# RS1xxxx register map
Vendor: Silicon Lab Inc.; Series: ARMCM4; File version: 1.2
CPU: CM4 r1p0, little endian, MPU, FPU, 6 interrupt priority bits
Registers are 32-bit, read-write, reset 0x0 unless marked. A register's access mark holds for its fields unless they carry their own. Offsets are from the block's base; [hi:lo] are bit positions; {n}, {i} and the like mark numbered series.

## M4CLK — MCU HP (High Performance) domain contains the Cortex-M4F Processor, FPU, Debugger, MCU High Speed Interfaces, MCU HP Peripherals, MCU HP DMA and MCU/SZP shareable Interfaces
Base 0x46000000
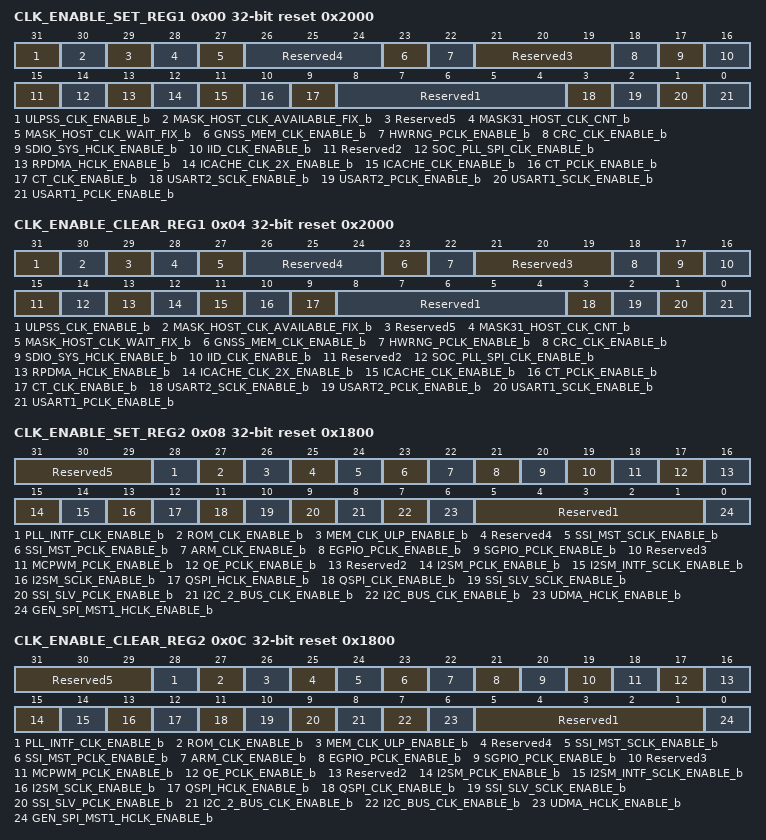
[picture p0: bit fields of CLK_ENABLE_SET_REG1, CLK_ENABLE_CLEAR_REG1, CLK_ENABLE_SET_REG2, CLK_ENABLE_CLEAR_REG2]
0x00 CLK_ENABLE_SET_REG1 reset 0x2000 — Clock Enable Set Register 1
  [31] ULPSS_CLK_ENABLE_b — Static Clock gating Enable for m4 soc_clk to ulpss1'b1 => Clock is enabled 1'b0 => Invalid.
  [30] MASK_HOST_CLK_AVAILABLE_FIX_b — This bit decides whether to consider negedge of host_clk_available in the generation of clock enable for host_clk gate in host mux 1'b1 => Don't consider 1'b0 => Invalid This bit along with mask_host_clk_wait_fix and mask31_host_clk_cnt are to take care in case of any bugs.
  [29] Reserved5 — It is recommended to write these bits to 0.
  [28] MASK31_HOST_CLK_CNT_b — When mask_host_clk_wait_fix is 1'b1, this bit decides whether to count for 32 0r 16 xtal clock cycles to come out of WAIT state in host mux FSM 1'b1 => Wait for 32 clock cycles 1'b0 => Invalid This bit along with mask_host_clk_available_fix and mask_host_clk_wait_fix are to take care in case of any bugs.
  [27] MASK_HOST_CLK_WAIT_FIX_b — This bit decides whether to wait for a fixed number of xtal clock cycles(based on mask31_host_clk_cnt) or wait for a internally generated signal to come out of WAIT state in host mux FSM 1'b1 => Wait for fixed number of xtal clk cycles 1'b0 => Invalid This bit along with mask_host_clk_available_fix and mask31_host_clk_cnt are to take care in case of any bugs.
  [26:24] Reserved4 — It is recommended to write these bits to 0.
  [23] GNSS_MEM_CLK_ENABLE_b — Static Clock gating Enable for GNSS mem clk1'b1 => Clock is enabled 1'b0 => Invalid
  [22] HWRNG_PCLK_ENABLE_b — Static Clock gating Enable for HWRNG pclk1'b1 => Clock is enabled 1'b0 => Invalid.
  [21:19] Reserved3 — It is recommended to write these bits to 0.
  [18] CRC_CLK_ENABLE_b — Static Clock gating Enable for crc clk1'b1 => Clock is enabled 1'b0 => Invalid
  [17] SDIO_SYS_HCLK_ENABLE_b — Static Clock gating Enable for sdio sys hclk1'b1 => Clock is enabled 1'b0 => Invalid
  [16] IID_CLK_ENABLE_b — Static Clock gating Enable for iid clk1'b1 => Clock is enabled 1'b0 => Invalid.
  [15] Reserved2 — It is recommended to write these bits to 0.
  [14] SOC_PLL_SPI_CLK_ENABLE_b — Static Clock gating Enable for soc pll spi clk1'b1 => Clock is enabled 1'b0 => Invalid.
  [13] RPDMA_HCLK_ENABLE_b — Static Clock gating Enable for rpdma hclk1'b1 => Clock is enabled 1'b0 => Invalid.
  [12] ICACHE_CLK_2X_ENABLE_b — Static Clock gating Enable for icache 2x clk1'b1 => Clock is enabled 1'b0 => Invalid.
  [11] ICACHE_CLK_ENABLE_b — Static Clock gating Enable for icache clk1'b1 => Clock is enabled 1'b0 => Invalid.
  [10] CT_PCLK_ENABLE_b — Static Clock gating Enable for sct pclk1'b1 => Clock is enabled 1'b0 => Invalid.
  [9] CT_CLK_ENABLE_b — Static Clock gating Enable for sct clk1'b1 => Clock is enabled 1'b0 => Invalid.
  [8:4] Reserved1 — It is recommended to write these bits to 0.
  [3] USART2_SCLK_ENABLE_b — Static Clock gating Enable for usart2 sclk1'b1 => Clock is enabled 1'b0 => Invalid
  [2] USART2_PCLK_ENABLE_b — Static Clock gating Enable for usart2 pclk1'b1 => Clock is enabled 1'b0 => Invalid
  [1] USART1_SCLK_ENABLE_b — Static Clock gating Enable for usart1 sclk1'b1 => Clock is enabled 1'b0 => Invalid
  [0] USART1_PCLK_ENABLE_b — Static Clock gating Enable for usart1 pclk1'b1 => Clock is enabled 1'b0 => Invalid
0x04 CLK_ENABLE_CLEAR_REG1 reset 0x2000 — Clock Enable Clear Register 1
  [31] ULPSS_CLK_ENABLE_b — Static Clock gating Enable for m4 soc_clk to ulpss1'b1 => Clock is enabled 1'b0 => Invalid.
  [30] MASK_HOST_CLK_AVAILABLE_FIX_b — This bit decides whether to consider negedge of host_clk_available in the generation of clock enable for host_clk gate in host mux 1'b1 => Don't consider 1'b0 => Invalid This bit along with mask_host_clk_wait_fix and mask31_host_clk_cnt are to take care in case of any bugs.
  [29] Reserved5 — It is recommended to write these bits to 0.
  [28] MASK31_HOST_CLK_CNT_b — When mask_host_clk_wait_fix is 1'b1, this bit decides whether to count for 32 0r 16 xtal clock cycles to come out of WAIT state in host mux FSM 1'b1 => Wait for 32 clock cycles 1'b0 => Invalid This bit along with mask_host_clk_available_fix and mask_host_clk_wait_fix are to take care in case of any bugs.
  [27] MASK_HOST_CLK_WAIT_FIX_b — This bit decides whether to wait for a fixed number of xtal clock cycles(based on mask31_host_clk_cnt) or wait for a internally generated signal to come out of WAIT state in host mux FSM 1'b1 => Wait for fixed number of xtal clk cycles 1'b0 => Invalid This bit along with mask_host_clk_available_fix and mask31_host_clk_cnt are to take care in case of any bugs.
  [26:24] Reserved4 — It is recommended to write these bits to 0.
  [23] GNSS_MEM_CLK_ENABLE_b — Static Clock Clear for GNSS mem clk1'b1 => Clock is Clear 1'b0 => Invalid
  [22] HWRNG_PCLK_ENABLE_b — Static Clock Clear for HWRNG pclk1'b1 => Clock is Clear 1'b0 => Invalid.
  [21:19] Reserved3 — It is recommended to write these bits to 0.
  [18] CRC_CLK_ENABLE_b — Static Clock Clear for crc clk1'b1 => Clock is Clear 1'b0 => Invalid
  [17] SDIO_SYS_HCLK_ENABLE_b — Static Clock Clear for sdio sys hclk1'b1 => Clock is Clear 1'b0 => Invalid
  [16] IID_CLK_ENABLE_b — Static Clock Clear for iid clk1'b1 => Clock is Clear 1'b0 => Invalid.
  [15] Reserved2 — It is recommended to write these bits to 0.
  [14] SOC_PLL_SPI_CLK_ENABLE_b — Static Clock Clear for soc pll spi clk1'b1 => Clock is Clear 1'b0 => Invalid.
  [13] RPDMA_HCLK_ENABLE_b — Static Clock Clear for rpdma hclk1'b1 => Clock is Clear 1'b0 => Invalid.
  [12] ICACHE_CLK_2X_ENABLE_b — Static Clock Clear for icache 2x clk1'b1 => Clock is Clear 1'b0 => Invalid.
  [11] ICACHE_CLK_ENABLE_b — Static Clock Clear for icache clk1'b1 => Clock is Clear 1'b0 => Invalid.
  [10] CT_PCLK_ENABLE_b — Static Clock Clear for sct pclk1'b1 => Clock is Clear 1'b0 => Invalid.
  [9] CT_CLK_ENABLE_b — Static Clock Clear for sct clk1'b1 => Clock is Clear 1'b0 => Invalid.
  [8:4] Reserved1 — It is recommended to write these bits to 0.
  [3] USART2_SCLK_ENABLE_b — Static Clock Clear for usart2 sclk1'b1 => Clock is Clear 1'b0 => Invalid
  [2] USART2_PCLK_ENABLE_b — Static Clock Clear for usart2 pclk 1'b1 => Clock is Clear 1'b0 => Invalid
  [1] USART1_SCLK_ENABLE_b — Static Clock Clear for usart1 sclk1'b1 => Clock is Clear 1'b0 => Invalid
  [0] USART1_PCLK_ENABLE_b — Static Clock Clear for usart1 pclk1'b1 => Clock is Clear 1'b0 => Invalid
0x08 CLK_ENABLE_SET_REG2 reset 0x1800 — Clock Enable Set Register 2
  [31:29] Reserved5 — It is recommended to write these bits to 0.
  [28] PLL_INTF_CLK_ENABLE_b — Static Clock gating Enable for pll intf clk 1'b1 => Clock is enabled 1'b0 => Invalid.
  [27] ROM_CLK_ENABLE_b — Static Clock gating Enable for rom clk 1'b1 => Clock is enabled 1'b0 => Invalid.
  [26] MEM_CLK_ULP_ENABLE_b — Static Clock gating Enable for mem ulp clk 1'b1 => Clock is enabled 1'b0 => Invalid.
  [25] Reserved4 — It is recommended to write these bits to 0.
  [24] SSI_MST_SCLK_ENABLE_b — Static Clock gating Enable for ssi master sclk 1'b1 => Clock is enabled 1'b0 => Invalid.
  [23] SSI_MST_PCLK_ENABLE_b — Static Clock gating Enable for ssi master pclk 1'b1 => Clock is enabled 1'b0 => Invalid.
  [22] ARM_CLK_ENABLE_b — Static Clock gating Enable for arm clk 1'b1 => Clock is enabled 1'b0 => Invalid.
  [21] EGPIO_PCLK_ENABLE_b — Static Clock gating Enable for egpio pclk 1'b1 => Clock is enabled 1'b0 => Invalid.
  [20] SGPIO_PCLK_ENABLE_b — Static Clock gating Enable for sgpio pclk 1'b1 => Clock is enabled 1'b0 => Invalid.
  [19] Reserved3 — It is recommended to write these bits to 0.
  [18] MCPWM_PCLK_ENABLE_b — Static Clock gating Enable for mcpwm pclk 1'b1 => Clock is enabled 1'b0 => Invalid.
  [17] QE_PCLK_ENABLE_b — Static Clock gating Enable for qe pclk 1'b1 => Clock is enabled 1'b0 => Invalid.
  [16] Reserved2 — It is recommended to write these bits to 0.
  [15] I2SM_PCLK_ENABLE_b — Static Clock gating Enable for i2s master pclk 1'b1 => Clock is enabled 1'b0 => Invalid.
  [14] I2SM_INTF_SCLK_ENABLE_b — Static Clock gating Enable for i2s interface sclk 1'b1 => Clock is enabled 1'b0 => Invalid.
  [13] I2SM_SCLK_ENABLE_b — Static Clock gating Enable for sclk of I2S at Root Clock generation 1'b1 => Clock is enabled 1'b0 => Invalid.
  [12] QSPI_HCLK_ENABLE_b — Static Clock gating Enable for qspi hclk 1'b1 => Clock is enabled 1'b0 => Invalid.
  [11] QSPI_CLK_ENABLE_b — Static Clock gating Enable for qspi clk 1'b1 => Clock is enabled 1'b0 => Invalid.
  [10] SSI_SLV_SCLK_ENABLE_b — Static Clock gating Enable for ssi slave sclk 1'b1 => Clock is enabled 1'b0 => Invalid.
  [9] SSI_SLV_PCLK_ENABLE_b — Static Clock gating Enable for ssi slave pclk 1'b1 => Clock is enabled 1'b0 => Invalid.
  [8] I2C_2_BUS_CLK_ENABLE_b — Static Clock gating Enable for i2c-2 bus clk 1'b1 => Clock is enabled 1'b0 => Invalid.
  [7] I2C_BUS_CLK_ENABLE_b — Static Clock gating Enable for i2c-1 bus clk1'b1 => Clock is enabled 1'b0 => Invalid.
  [6] UDMA_HCLK_ENABLE_b — Static Clock gating Enable for udma hclk 1'b1 => Clock is enabled 1'b0 => Invalid.
  [5:1] Reserved1 — It is recommended to write these bits to 0.
  [0] GEN_SPI_MST1_HCLK_ENABLE_b — Static Clock gating Enable for gen spi master1 hclk 1'b1 => Clock is enabled 1'b0 => Invalid
0x0C CLK_ENABLE_CLEAR_REG2 reset 0x1800 — Clock Enable Clear Register 2
  [31:29] Reserved5 — It is recommended to write these bits to 0.
  [28] PLL_INTF_CLK_ENABLE_b — Static Clock Clear for pll intf clk 1'b1 => Clock is Clear 1'b0 => Invalid.
  [27] ROM_CLK_ENABLE_b — Static Clock Clear for rom clk 1'b1 => Clock is Clear 1'b0 => Invalid.
  [26] MEM_CLK_ULP_ENABLE_b — Static Clock Clear for mem ulp clk 1'b1 => Clock is Clear 1'b0 => Invalid.
  [25] Reserved4 — It is recommended to write these bits to 0.
  [24] SSI_MST_SCLK_ENABLE_b — Static Clock Clear for ssi master sclk 1'b1 => Clock is Clear 1'b0 => Invalid.
  [23] SSI_MST_PCLK_ENABLE_b — Static Clock Clear for ssi master pclk 1'b1 => Clock is Clear 1'b0 => Invalid.
  [22] ARM_CLK_ENABLE_b — Static Clock Clear for arm clk 1'b1 => Clock is Clear 1'b0 => Invalid.
  [21] EGPIO_PCLK_ENABLE_b — Static Clock Clear for egpio pclk 1'b1 => Clock is Clear 1'b0 => Invalid.
  [20] SGPIO_PCLK_ENABLE_b — Static Clock Clear for sgpio pclk 1'b1 => Clock is Clear 1'b0 => Invalid.
  [19] Reserved3 — It is recommended to write these bits to 0.
  [18] MCPWM_PCLK_ENABLE_b — Static Clock Clear for mcpwm pclk 1'b1 => Clock is Clear 1'b0 => Invalid.
  [17] QE_PCLK_ENABLE_b — Static Clock Clear for qe pclk 1'b1 => Clock is Clear 1'b0 => Invalid.
  [16] Reserved2 — It is recommended to write these bits to 0.
  [15] I2SM_PCLK_ENABLE_b — Static Clock Clear for i2s master pclk 1'b1 => Clock is Clear 1'b0 => Invalid.
  [14] I2SM_INTF_SCLK_ENABLE_b — Static Clock Clear for i2s interface sclk 1'b1 => Clock is Clear 1'b0 => Invalid.
  [13] I2SM_SCLK_ENABLE_b — Static Clock Clear for sclk of I2S at Root Clock generation 1'b1 => Clock is Clear 1'b0 => Invalid.
  [12] QSPI_HCLK_ENABLE_b — Static Clock Clear for qspi hclk 1'b1 => Clock is Clear 1'b0 => Invalid.
  [11] QSPI_CLK_ENABLE_b — Static Clock Clear for qspi clk 1'b1 => Clock is Clear 1'b0 => Invalid.
  [10] SSI_SLV_SCLK_ENABLE_b — Static Clock Clear for ssi slave sclk 1'b1 => Clock is Clear 1'b0 => Invalid.
  [9] SSI_SLV_PCLK_ENABLE_b — Static Clock Clear for ssi slave pclk 1'b1 => Clock is Clear 1'b0 => Invalid.
  [8] I2C_2_BUS_CLK_ENABLE_b — Static Clock Clear for i2c-2 bus clk 1'b1 => Clock is Clear 1'b0 => Invalid.
  [7] I2C_BUS_CLK_ENABLE_b — Static Clock Clear for i2c-1 bus clk1'b1 => Clock is Clear 1'b0 => Invalid.
  [6] UDMA_HCLK_ENABLE_b — Static Clock Clear for udma hclk 1'b1 => Clock is Clear 1'b0 => Invalid.
  [5:1] Reserved1 — It is recommended to write these bits to 0.
  [0] GEN_SPI_MST1_HCLK_ENABLE_b — Static Clock Clear for gen spi master1 hclk 1'b1 => Clock is Clear 1'b0 => Invalid
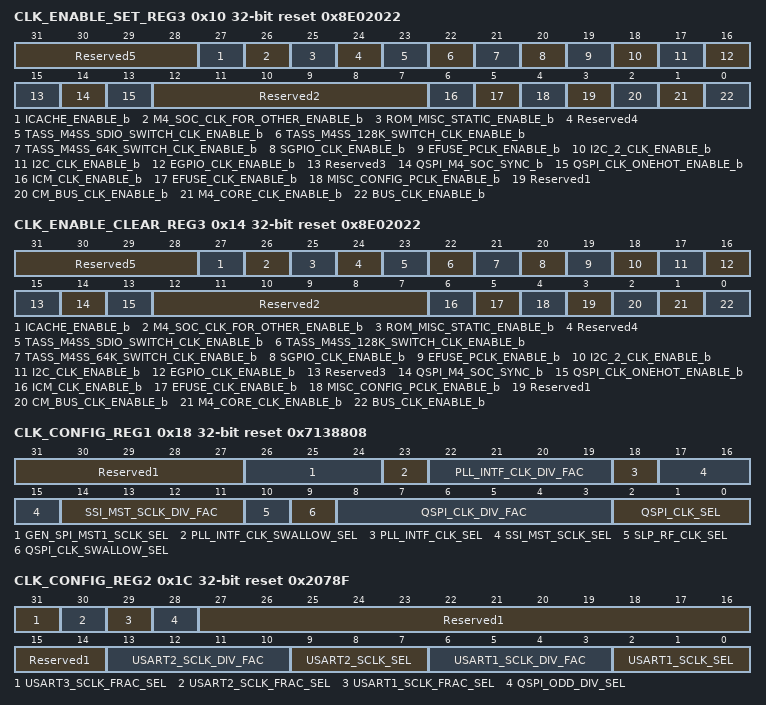
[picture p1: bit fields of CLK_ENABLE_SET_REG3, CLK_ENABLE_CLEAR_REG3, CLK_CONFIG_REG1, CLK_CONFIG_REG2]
0x10 CLK_ENABLE_SET_REG3 reset 0x8E02022 — Clock Enable Set Register 3
  [31:28] Reserved5 — It is recommended to write these bits to 0.
  [27] ICACHE_ENABLE_b — Static Clock gating enable for Icache. This has to be enable for Icache operations. 1b1 - Clock is enabled 1b0 - Invalid.
  [26] M4_SOC_CLK_FOR_OTHER_ENABLE_b — Static Clock gating enable for M4-SOC Other Clock 1b1 - Clock is enabled 1b0 - Invalid.
  [25] ROM_MISC_STATIC_ENABLE_b — Static Clock gating enable for rom ahb Clock 1b1 - Clock is enabled 1b0 - Invalid.
  [24] Reserved4 — It is recommended to write these bits to 0.
  [23] TASS_M4SS_SDIO_SWITCH_CLK_ENABLE_b — Unused.
  [22] TASS_M4SS_128K_SWITCH_CLK_ENABLE_b — Unused.
  [21] TASS_M4SS_64K_SWITCH_CLK_ENABLE_b — Unused.
  [20] SGPIO_CLK_ENABLE_b — Static Clock gating enable for SIO Module 1b1 - Clock is enabled 1b0 - Invalid.
  [19] EFUSE_PCLK_ENABLE_b — Static Clock gating enable for EFUSE APB Interface 1b1 - Clock is enabled 1b0 - Invalid.
  [18] I2C_2_CLK_ENABLE_b — Static Clock gating enable for I2C-2 Module 1b1 - Clock is enabled 1b0 - Invalid.
  [17] I2C_CLK_ENABLE_b — Static Clock gating enable for I2C-1 Module 1b1 - Clock is enabled 1b0 - Invalid.
  [16] EGPIO_CLK_ENABLE_b — Static Clock gating enable for Enhanced-GPIO 1b1 - Clock is enabled 1b0 - Invalid.
  [15] Reserved3 — It is recommended to write these bits to 0.
  [14] QSPI_M4_SOC_SYNC_b — Specifies whether QSPI clock is in sync with Soc clock. Before enabling this make sure that qspi_clk_onehot_enable is 1b0 to enable glitch free switching 1b1 - QSPI clock is in sync with M4 clock 1b0 - Invalid.
  [13] QSPI_CLK_ONEHOT_ENABLE_b — Static Clock gating Enable for QSPI clock generated from the dynamic mux 1b1 - Clock is enabled 1b0 - Invalid.
  [12:7] Reserved2 — It is recommended to write these bits to 0.
  [6] ICM_CLK_ENABLE_b — Static Clock gating Enable for icm clk 1'b1 => Clock is enabled 1'b0 => Invalid.
  [5] EFUSE_CLK_ENABLE_b — Static Clock gating Enable for efuse clk 1'b1 => Clock is enabled 1'b0 => Invalid.
  [4] MISC_CONFIG_PCLK_ENABLE_b — Static Clock gating Enable for misc config regs clk 1'b1 => Clock is enabled 1'b0 => Invalid.
  [3] Reserved1 — It is recommended to write these bits to 0.
  [2] CM_BUS_CLK_ENABLE_b — Static Clock gating Enable for cm bus clk1'b1 => Clock is enabled1'b0 => Invalid.
  [1] M4_CORE_CLK_ENABLE_b — Static Clock gating Enable for M4 Core clk 1'b1 => Clock is enabled 1'b0 => Invalid.
  [0] BUS_CLK_ENABLE_b — Static Clock gating Enable for bus clk 1'b1 => Clock is enabled 1'b0 => Invalid
0x14 CLK_ENABLE_CLEAR_REG3 reset 0x8E02022 — Clock Enable Clear Register 3
  [31:28] Reserved5 — It is recommended to write these bits to 0.
  [27] ICACHE_ENABLE_b — Static Clock Disable for Icache. This has to be enable for Icache operations. 1b1 - Clock is Disable 1b0 - Invalid.
  [26] M4_SOC_CLK_FOR_OTHER_ENABLE_b — Static Clock Disable for M4-SOC Other Clock 1b1 - Clock is Disable 1b0 - Invalid.
  [25] ROM_MISC_STATIC_ENABLE_b — Static Clock Disable for rom ahb Clock 1b1 - Clock is Disable 1b0 - Invalid.
  [24] Reserved4 — It is recommended to write these bits to 0.
  [23] TASS_M4SS_SDIO_SWITCH_CLK_ENABLE_b — Unused.
  [22] TASS_M4SS_128K_SWITCH_CLK_ENABLE_b — Unused.
  [21] TASS_M4SS_64K_SWITCH_CLK_ENABLE_b — Unused.
  [20] SGPIO_CLK_ENABLE_b — Static Clock gating enable for SIO Module 1b1 - Clock is enabled 1b0 - Invalid.
  [19] EFUSE_PCLK_ENABLE_b — Static Clock Disable for EFUSE APB Interface 1b1 - Clock is Disable 1b0 - Invalid.
  [18] I2C_2_CLK_ENABLE_b — Static Clock Disable for I2C-2 Module 1b1 - Clock is Disable 1b0 - Invalid.
  [17] I2C_CLK_ENABLE_b — Static Clock Disable for I2C-1 Module 1b1 - Clock is Disable 1b0 - Invalid.
  [16] EGPIO_CLK_ENABLE_b — Static Clock Disable for Enhanced-GPIO 1b1 - Clock is Disable 1b0 - Invalid.
  [15] Reserved3 — It is recommended to write these bits to 0.
  [14] QSPI_M4_SOC_SYNC_b — Specifies whether QSPI clock is in sync with Soc clock. Before enabling this make sure that qspi_clk_onehot_enable is 1b0 to enable glitch free switching 1b1 - QSPI clock is in sync with M4 clock 1b0 - Invalid.
  [13] QSPI_CLK_ONEHOT_ENABLE_b — Static Clock Clear for QSPI clock generated from the dynamic mux 1b1 - Clock is Gated 1b0 - Invalid.
  [12:7] Reserved2 — It is recommended to write these bits to 0.
  [6] ICM_CLK_ENABLE_b — Static Clock Clear for icm clk 1'b1 => Clock is Clear 1'b0 => Invalid.
  [5] EFUSE_CLK_ENABLE_b — Static Clock Clear for efuse clk 1'b1 => Clock is Clear 1'b0 => Invalid.
  [4] MISC_CONFIG_PCLK_ENABLE_b — Static Clock Clear for misc config regs clk 1'b1 => Clock is Clear 1'b0 => Invalid.
  [3] Reserved1 — It is recommended to write these bits to 0.
  [2] CM_BUS_CLK_ENABLE_b — Static Clock gating Enable for cm bus clk1'b1 => Clock is enabled1'b0 => Invalid.
  [1] M4_CORE_CLK_ENABLE_b — Static Clock Clear for M4 Core clk 1'b1 => Clock is Clear 1'b0 => Invalid.
  [0] BUS_CLK_ENABLE_b — Static Clock Clear for bus clk 1'b1 => Clock is Clear 1'b0 => Invalid
0x18 CLK_CONFIG_REG1 reset 0x7138808 — Clock Config Register 1
  [31:27] Reserved1 — It is recommended to write these bits to 0.
  [26:24] GEN_SPI_MST1_SCLK_SEL — Selects one of the following clocks for USART1 clk 000 - m4_soc_clk_for_other_clocks 001 - ulp ref Clock(generated inside M4SS based on m4ss_ref_clk_sel from NPSS) 010 - SoC PLL Clock(program bypass_soc_pll_clk if the bypass clock has to be selected) 011 - Modem PLL Clock2(Not Intended for the pragrammer) (program bypass_modem_pll_clk if the bypass clock has to be selected) 100 - Intf PLL Clock(program bypass_intf_pll_clk if the bypass clock has to be selected) 101 to 110 - Invalid 111 - Gated
  [23] PLL_INTF_CLK_SWALLOW_SEL — Clock select for clock swallow or clock divider for PLL INTF Clk 1b0 - 50% divider is selected with division factor 2; 1b1 - Swallowed clock is selected with division factor pll_intf_clk_div_fac
  [22:19] PLL_INTF_CLK_DIV_FAC — Clock division factor for pll_intf_clk. If pll_intf_clk_enable is 1b0 clock is gated. Else, when pll_intf_clk_swallow_sel is 1b1, output clock is a swallowed clock. when pll_intf_clk_swallow_sel is 1b0, output clock is a 50 Per duty cycle clock.
  [18] PLL_INTF_CLK_SEL — Selects one of the following clocks for pll intf clock 0 - Intf Pll Clock(program bypass_intf_pll_clk if the bypass clock has to be selected) 1 - SoC Pll Clock(program bypass_soc_pll_clk if the bypass clock has to be selected)
  [17:15] SSI_MST_SCLK_SEL — Selects one of the following clocks for ssi master 000 - ULP Ref Clock(generated inside M4SS based on m4ss_ref_clk_sel from NPSS) 001 - SoC PLL Clock(program bypass_soc_pll_clk if the bypass clock has to be selected) 010 - Modem PLL Clock1(Not Intended for the programmer) (program bypass_modem_pll_clk if the bypass clock has to be selected) 011 - Intf PLL Clock(program bypass_intf_pll_clk if the bypass clock has to be selected) 100 - Modem PLL Clock2(Not Intended for the pragrammer) (program bypass_modem_pll_clk if the bypass clock has to be selected) 101 - m4_soc_clk_for_other_clks 110 - Invalid 111 - Gated.
  [14:11] SSI_MST_SCLK_DIV_FAC — Clock division factor for ssi_mst_sclk. If ssi_mst_sclk_enable is 1b0 clock is gated. Else output clock is a swallowed clock with the following frequency. 4h0,4h1 => Divider is bypassed >4h1 => clk_out = clk_in/ ssi_mst_sclk_div_fac.
  [10] SLP_RF_CLK_SEL — clock select for m4_soc_rf_ref_clk 0 - m4_soc_clk 1 - rf_ref_clk.
  [9] QSPI_CLK_SWALLOW_SEL — Clock select for clock swallow or clock divider for QSPI 1b0 => 50% divider is selected with division factor qspi_clk_div_fac 1b1 => Swallowed clock is selected with division factor qspi_clk_div_fac Before Changing this ensure that the input clocks are gated
  [8:3] QSPI_CLK_DIV_FAC — Clock divison factor for QSPI. If qspi_clk_enable is 1b0 clock is gated. Else 1)when qspi_clk_swallow_sel is 1b1 and qspi_odd_div_sel is 1b0 output clock is a swallowed clock with the following frequency. 6h0,6h1 => clk_out = clk_in >6h1 => clk_out = clk_in/ qspi_clk_div_fac 2)when qspi_clk_swallow_sel is 1b0 and qspi_odd_div_sel is 1b0 output clock is a 50% duty cycle clock with the following frequency. 6h0 => clk_out = clk_in/2 >6h0 => clk_out = clk_in/ (2*qspi_clk_div_fac) 3)When qspi_odd_div_sel is 1b1, output clock is a 50% duty cycle clock with the following frequency. clk_out = clk_in/qspi_clk_div_fac when qspi_clk_div_fac is an odd number >=3, else output clock is gated
  [2:0] QSPI_CLK_SEL — Selects one of the following clocks for ssi master 000 - ULP Ref Clock(generated inside M4SS based on m4ss_ref_clk_sel from NPSS) 001 - Intf PLL Clock Clock (program bypass_intf_pll_clk if the bypass clock has to be selected) 010 - Modem PLL Clock2(Not Intended for the programmer) (program bypass_modem_pll_clk if the bypass clock has to be selected) 011 - SoC PLL Clock Clock (program bypass_soc_pll_clk if the bypass clock has to be selected) 100 to 110 - Invalid 111 - Gated
0x1C CLK_CONFIG_REG2 reset 0x2078F — Clock Config Register 1
  [31] USART3_SCLK_FRAC_SEL — Selects the type of divider for uart3_clk 1b0 - Clock Swallow is selected 1b1 - Fractional Divider is selected.
  [30] USART2_SCLK_FRAC_SEL — Selects the type of divider for uart2_clk 1b0 - Clock Swallow is selected 1b1 - Fractional Divider is selected.
  [29] USART1_SCLK_FRAC_SEL — Selects the type of divider for uart1_clk 1b0 - Clock Swallow is selected 1b1 - Fractional Divider is selected.
  [28] QSPI_ODD_DIV_SEL — Clock select for clock swallow or 50% even clock divider or 50% odd divider clock for QSPI 1b1 - 50% odd clock divider output is selected with division factor qspi_clk_div_fac 1b0 - 50% even clock divider output or swallowed is selected with division factor qspi_clk_div_fac based on qspi_clk_swallow_sel.
  [27:14] Reserved1 — It is recommended to write these bits to 0.
  [13:10] USART2_SCLK_DIV_FAC — Clock division factor for USART2 Clock. If usart2_sclk_enable is 1b0 clock is gated. Else output clock is a swallowed clock.
  [9:7] USART2_SCLK_SEL — Selects one of the following clocks for USART2 clk 000 - ulp ref Clock(generated inside M4SS based on m4ss_ref_clk_sel from NPSS) 001 - SoC PLL Clock(program bypass_soc_pll_clk if the bypass clock has to be selected) 010 - Modem PLL Clock2(Not Intended for the pragrammer)(program bypass_modem_pll_clk if the bypass clock has to be selected) 011 - Intf PLL Clock(program bypass_intf_pll_clk if the bypass clock has to be selected) 100 - m4_soc_clk_for_other_clocks 101 to 110 - Invalid 111 - Gated
  [6:3] USART1_SCLK_DIV_FAC — Clock division factor for USART1 Clock. If usart1_sclk_enable is 1b0 clock is gated. Else output clock is a swallowed clock.
  [2:0] USART1_SCLK_SEL — Selects one of the following clocks for USART1 clk 000 - ulp ref Clock(generated inside M4SS based on m4ss_ref_clk_sel from NPSS) 001 - SoC PLL Clock(program bypass_soc_pll_clk if the bypass clock has to be selected) 010 - Modem PLL Clock2(Not Intended for the pragrammer)(program bypass_modem_pll_clk if the bypass clock has to be selected) 011 - Intf PLL Clock(program bypass_intf_pll_clk if the bypass clock has to be selected) 100 - m4_soc_clk_for_other_clocks 101 to 110 - Invalid 111 - Gated
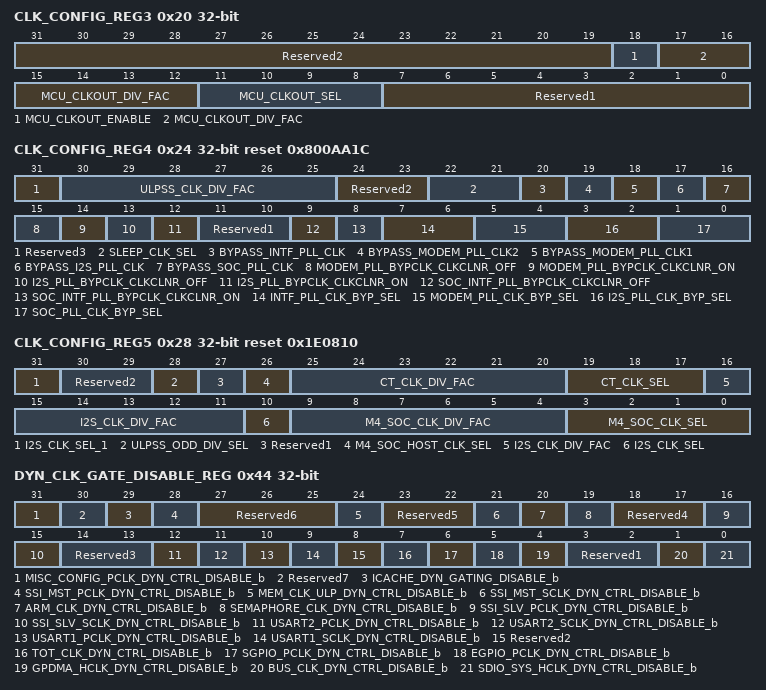
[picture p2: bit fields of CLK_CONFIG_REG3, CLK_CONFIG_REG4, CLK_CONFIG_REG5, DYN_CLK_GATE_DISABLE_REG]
0x20 CLK_CONFIG_REG3 — Clock Config Register 3
  [31:19] Reserved2 — It is recommended to write these bits to 0.
  [18] MCU_CLKOUT_ENABLE — Clock Enable for the clock on nwp_clkout (Mapped to GPIO) 1b0 - Clock is Gated 1b1 - Clock is Enabled
  [17:12] MCU_CLKOUT_DIV_FAC — Division factor for mcu_clkout (Mapped to GPIO)
  [11:8] MCU_CLKOUT_SEL — Clock Select for the clock on mcu_clkout (Mapped to GPIO)
  [7:0] Reserved1 — It is recommended to write these bits to 0.
0x24 CLK_CONFIG_REG4 reset 0x800AA1C — Clock Config Register 4
  [31] Reserved3 — It is recommended to write these bits to 0.
  [30:25] ULPSS_CLK_DIV_FAC — Clock division factor for clock to ULPSS. If ulpss_clk_enable is 1b0 clock is gated. Else output clock is a divided clock with the following frequency. 6h0 - Divider is bypassed > 6h0 - clk_out = clk_in/ 2* ulpss_clk_div_fac
  [24:23] Reserved2 — It is recommended to write these bits to 0.
  [22:21] SLEEP_CLK_SEL — Select to choose sleep clk 00 - ulp_32khz_rc_clk 01 - ulp_32khz_xtal_clk 10 - Gated 11 - ulp_32khz_ro_clk.
  [20] BYPASS_INTF_PLL_CLK — Select to choose bypass clock or PLL clock 1b0 - intf_pll_clk 1b1 - One of the bypass clocks based on soc_pll_clk_byp_sel.
  [19] BYPASS_MODEM_PLL_CLK2 — Select to choose bypass clock or PLL clock 1b0 - modem_pll_clk2 1b1 - One of the bypass clocks based on modem_pll_clk_byp_sel.
  [18] BYPASS_MODEM_PLL_CLK1 — Select to choose bypass clock or PLL clock 1b0 - modem_pll_clk1 1b1 - One of the bypass clocks based on modem_pll_clk_byp_sel.
  [17] BYPASS_I2S_PLL_CLK — Select to choose bypass clock or PLL clock 1b0 - i2s_pll_clk 1b1 - One of the bypass clocks based on soc_pll_clk_byp_sel.
  [16] BYPASS_SOC_PLL_CLK — Select to choose bypass clock or PLL clock 1b0 - soc_pll_clk 1b1 - One of the bypass clocks based on soc_pll_clk_byp_sel.
  [15] MODEM_PLL_BYPCLK_CLKCLNR_OFF — Clock cleaner OFF Control for Modem PLL Bypass Clock.
  [14] MODEM_PLL_BYPCLK_CLKCLNR_ON — Clock cleaner ON Control for Modem PLL Bypass Clock.
  [13] I2S_PLL_BYPCLK_CLKCLNR_OFF — Clock cleaner OFF Control for I2S PLL Bypass Clock.
  [12] I2S_PLL_BYPCLK_CLKCLNR_ON — Clock cleaner ON Control for I2S PLL Bypass Clock.
  [11:10] Reserved1 — It is recommended to write these bits to 0.
  [9] SOC_INTF_PLL_BYPCLK_CLKCLNR_OFF — Clock cleaner OFF Control for SoC PLL Bypass Clock
  [8] SOC_INTF_PLL_BYPCLK_CLKCLNR_ON — Clock cleaner ON Control for SoC PLL Bypass Clock
  [7:6] INTF_PLL_CLK_BYP_SEL — Selects one of the bypass clocks for Intf PLL Clock
  [5:4] MODEM_PLL_CLK_BYP_SEL — Selects one of the bypass clocks for Modem PLL Clock
  [3:2] I2S_PLL_CLK_BYP_SEL — Selects one of the bypass clocks for I2S PLL Clock
  [1:0] SOC_PLL_CLK_BYP_SEL — Selects one of the bypass clocks for SoC PLL Clock
0x28 CLK_CONFIG_REG5 reset 0x1E0810 — Clock Config Register 5
  [31] I2S_CLK_SEL_1 — Selects one of the following clocks for config timer for I2S interface 00/11 - I2S PLL Clock (program bypass_i2s_pll_clk if the bypass clock has to be selected) 01 - I2S PLL Clock_1 (program bypass_i2s_pll_clk_1 if the bypass clock has to be selected) 10 - m4_soc_clk_for_other_clocks
  [30:29] Reserved2 — It is recommended to write these bits to 0.
  [28] ULPSS_ODD_DIV_SEL — Selects the type of divider for m4_soc_clk_2ulpss 1b0 - Clock Divider(even) is selected 1b1 - Odd Divider is selected.
  [27] Reserved1 — It is recommended to write these bits to 0.
  [26] M4_SOC_HOST_CLK_SEL — Selects the previous muxed output(xtal_clk) or host_clk as the clock source for M4 SoC clock based on the following combinations of {xtal_off(from slp fsm), host_clk_available(from host logic),m4_soc_host_clk_sel} XX0 - xtal_clk 001 - After wait time based on mask_host_clk_wait_fix ; xtal_clk X11 - host_clk 101 - No Clock
  [25:20] CT_CLK_DIV_FAC — Clock division factor for sct_clk. If sct_clk_enable is 1b0 clock is gated. Else output clock is a 50% divided clock with the following frequency. 6h0 - Divider is bypassed >6h0 - clk_out = clk_in/ 2*sct_clk_div_fac
  [19:17] CT_CLK_SEL — Selects one of the following clocks for config timer 000 - ulp ref Clock(generated inside M4SS based on m4ss_ref_clk_sel from NPSS) 001 - Intf PLL Clock(program bypass_intf_pll_clk if the bypass clock has to be selected) 010 - SoC PLL Clock(program bypass_soc_pll_clk if the bypass clock has to be selected) 011 - m4_soc_clk_for_other_clocks 100,110 - Invalid 111 - Gated
  [16:11] I2S_CLK_DIV_FAC — Clock division factor for i2s_clk. Else output clock is a 50% divided clock with the following frequency. 6h0 - Divider is bypassed >6h0 - clk_out = clk_in/ 2*i2s_clk_div_fac
  [10] I2S_CLK_SEL — Selects one of the following clocks for config timer I2S interface 00/11 - I2S PLL Clock (program bypass_i2s_pll_clk if the bypass clock has to be selected) 01 - I2S PLL Clock_1 (program bypass_i2s_pll_clk_1 if the bypass clock has to be selected) 10 - m4_soc_clk_for_other_clocks
  [9:4] M4_SOC_CLK_DIV_FAC — Clock divison factor for TA SoC Clock If ta_soc_clk_enable(from NPSS) is 1b0 clock is gated. Else output clock is a swallowed clock with the following frequency. 6h0,6h1 - Divider is bypassed >6h1 - clk_out = clk_in/ ta_soc_clk_div_fac
  [3:0] M4_SOC_CLK_SEL — Selects one of the clock sources for M4 SoC clock. These clocks are selected for m4_soc_clk when 1)m4_soc_host_clk_sel is 1b0 or 2)when m4_soc_host_clk_sel is 1b1, xtal is ON(xtal_off from slp_fsm should be zero) and host_clk_available(from host logic) is 1b0. 0000 - ULP Ref Clock (generated inside M4SS based on m4ss_ref_clk_sel from NPSS) 0001 - Reserved 0010 - Soc PLL Clock (program bypass_soc_pll_clk if the bypass clock has to be selected) 0011 - Modem PLL Clock1 (Not Intended for the pragrammer) (program bypass_modem_pll_clk if the bypass clock has to be selected) 0100 - Intf PLL Clock (program bypass_intf_pll_clk if the bypass clock has to be selected) 0101 - Sleep Clock(generated inside M4SS based on sleep_clk_sel. Please select the proper sleep clock select before using this) 0110 to 1111 - Invalid
0x44 DYN_CLK_GATE_DISABLE_REG — Dynamic Clock Gate Disable Register
  [31] MISC_CONFIG_PCLK_DYN_CTRL_DISABLE_b — Dynamic clock gate disable control miscn config pclk 1'b0 => Dynamic control of the clock is disbaled 1'b1 => Dynamic control of the clock is enabled.
  [30] Reserved7 — It is recommended to write these bits to 0.
  [29] ICACHE_DYN_GATING_DISABLE_b — Dynamic clock gate disable control icache clk1'b0 => Dynamic control of the clock is disbaled 1'b1 => Dynamic control of the clock is enabled
  [28] SSI_MST_PCLK_DYN_CTRL_DISABLE_b — Dynamic clock gate disable control ssi mst pclk 1'b0 => Dynamic control of the clock is disbaled 1'b1 => Dynamic control of the clock is enabled
  [27:25] Reserved6 — It is recommended to write these bits to 0.
  [24] MEM_CLK_ULP_DYN_CTRL_DISABLE_b — Dynamic clock gate disable control mem clk1'b0 => Dynamic control of the clock is disbaled 1'b1 => Dynamic control of the clock is enabled.
  [23:22] Reserved5 — It is recommended to write these bits to 0.
  [21] SSI_MST_SCLK_DYN_CTRL_DISABLE_b — Dynamic clock gate disable control ssi mst sclk1'b0 => Dynamic control of the clock is disbaled 1'b1 => Dynamic control of the clock is enabled.
  [20] ARM_CLK_DYN_CTRL_DISABLE_b — Dynamic clock gate disable control arm clk1'b0 => Dynamic control of the clock is disbaled 1'b1 => Dynamic control of the clock is enabled.
  [19] SEMAPHORE_CLK_DYN_CTRL_DISABLE_b — Dynamic clock gate disable control semaphore clk1'b0 => Dynamic control of the clock is disbaled 1'b1 => Dynamic control of the clock is enabled.
  [18:17] Reserved4 — It is recommended to write these bits to 0.
  [16] SSI_SLV_PCLK_DYN_CTRL_DISABLE_b — Dynamic clock gate disable control ssi slave pclk1'b0 => Dynamic control of the clock is disbaled 1'b1 => Dynamic control of the clock is enabled
  [15] SSI_SLV_SCLK_DYN_CTRL_DISABLE_b — Dynamic clock gate disable control ssi slave sclk1'b0 => Dynamic control of the clock is disbaled 1'b1 => Dynamic control of the clock is enabled
  [14:13] Reserved3 — It is recommended to write these bits to 0.
  [12] USART2_PCLK_DYN_CTRL_DISABLE_b — Dynamic clock gate disable control usart2 pclk1'b0 => Dynamic control of the clock is disbaled 1'b1 => Dynamic control of the clock is enabled.
  [11] USART2_SCLK_DYN_CTRL_DISABLE_b — Dynamic clock gate disable control usart2 sclk1'b0 => Dynamic control of the clock is disbaled 1'b1 => Dynamic control of the clock is enabled.
  [10] USART1_PCLK_DYN_CTRL_DISABLE_b — Dynamic clock gate disable control usart1 pclk1'b0 => Dynamic control of the clock is disbaled 1'b1 => Dynamic control of the clock is enabled.
  [9] USART1_SCLK_DYN_CTRL_DISABLE_b — Dynamic clock gate disable control usart1 sclk1'b0 => Dynamic control of the clock is disbaled 1'b1 => Dynamic control of the clock is enabled.
  [8] Reserved2 — It is recommended to write these bits to 0.
  [7] TOT_CLK_DYN_CTRL_DISABLE_b — Dynamic clock gate disable control tot clk1'b0 => Dynamic control of the clock is disbaled 1'b1 => Dynamic control of the clock is enabled
  [6] SGPIO_PCLK_DYN_CTRL_DISABLE_b — Dynamic clock gate disable control sgpio clk1'b0 => Dynamic control of the clock is disbaled 1'b1 => Dynamic control of the clock is enabled
  [5] EGPIO_PCLK_DYN_CTRL_DISABLE_b — Dynamic clock gate disable control egpio clk1'b0 => Dynamic control of the clock is disbaled 1'b1 => Dynamic control of the clock is enabled
  [4] GPDMA_HCLK_DYN_CTRL_DISABLE_b — Dynamic clock gate disable control gpdma clk1'b0 => Dynamic control of the clock is disbaled 1'b1 => Dynamic control of the clock is enabled
  [3:2] Reserved1 — It is recommended to write these bits to 0.
  [1] BUS_CLK_DYN_CTRL_DISABLE_b — Dynamic clock gate disable control bus clk1'b0 => Dynamic control of the clock is disbaled 1'b1 => Dynamic control of the clock is enabled
  [0] SDIO_SYS_HCLK_DYN_CTRL_DISABLE_b — Dynamic clock gate disable control sdio sys clk1'b0 => Dynamic control of the clock is disbaled 1'b1 => Dynamic control of the clock is enabled
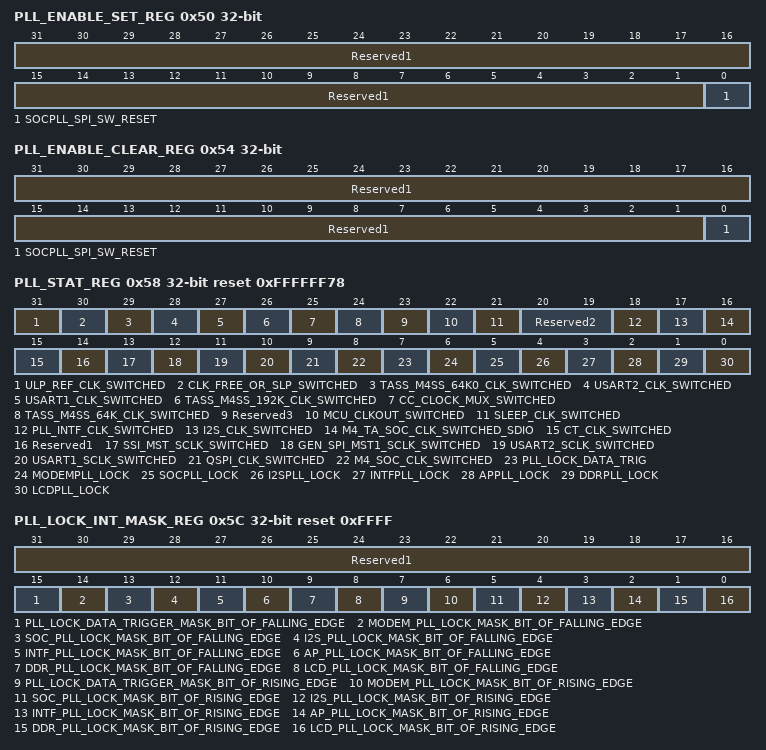
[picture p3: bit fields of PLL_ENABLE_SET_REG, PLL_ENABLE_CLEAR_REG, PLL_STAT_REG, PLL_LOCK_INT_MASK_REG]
0x50 PLL_ENABLE_SET_REG — PLL Enable Set Register
  [31:1] Reserved1 — It is recommended to write these bits to 0.
  [0] SOCPLL_SPI_SW_RESET — SPI soft reset for SoC PLL1'b1 => soft reset is enabled1'b0 => Invalid
0x54 PLL_ENABLE_CLEAR_REG — PLL Enable Clear Register
  [31:1] Reserved1 — It is recommended to write these bits to 0.
  [0] SOCPLL_SPI_SW_RESET — SPI soft reset for SoC PLL1'b1 => soft reset is disabled1'b0 => Invalid
0x58 PLL_STAT_REG ro reset 0xFFFFFF78 — PLL Status Register
  [31] ULP_REF_CLK_SWITCHED — Indication from ulp_ref_clk Dynamic mux that the switching happened
  [30] CLK_FREE_OR_SLP_SWITCHED — Indication from clk_free_or_slp Dynamic mux that the switching happened
  [29] TASS_M4SS_64K0_CLK_SWITCHED — Indication when TA accessing 1st memory chunk of M4, clock to Dynamic mux switching happened
  [28] USART2_CLK_SWITCHED — Indication from usart2 sclk or pclk Dynamic mux that the switching happened
  [27] USART1_CLK_SWITCHED — Indication from usart1 sclk or pclk Dynamic mux that the switching happened
  [26] TASS_M4SS_192K_CLK_SWITCHED — Indication when TA accessing 0th memory chunk of M4, clock to Dynamic mux switching happened
  [25] CC_CLOCK_MUX_SWITCHED — Indication from cc clock Dynamic mux that the switching happened
  [24] TASS_M4SS_64K_CLK_SWITCHED — Indication when TA accessing 2nd memory chunk of M4, clock to Dynamic mux switching happened
  [23] Reserved3 — It is recommended to write these bits to 0.
  [22] MCU_CLKOUT_SWITCHED — Indication from mcu_clkout Dynamic mux that the switching happened
  [21] SLEEP_CLK_SWITCHED — Indication from Sleep clcok Dynamic mux that the switching happened
  [20:19] Reserved2 — It is recommended to write these bits to 0.
  [18] PLL_INTF_CLK_SWITCHED — Indication from Pll Intf Clock Dynamic mux that the switching happened
  [17] I2S_CLK_SWITCHED — Indication from I2S Clock Dynamic mux that the switching happened
  [16] M4_TA_SOC_CLK_SWITCHED_SDIO — Indication from M4-TA Soc SDIO Clock Dynamic mux that the switching happened(TBD)
  [15] CT_CLK_SWITCHED — Indication from SCT Clock Dynamic mux that the switching happened
  [14] Reserved1 — It is recommended to write these bits to 0.
  [13] SSI_MST_SCLK_SWITCHED — Indication from SSi Master SClock Dynamic mux that the switching happened
  [12] GEN_SPI_MST1_SCLK_SWITCHED — Indication from USART2 Clock Dynamic mux that the switching happened
  [11] USART2_SCLK_SWITCHED — Indication from USART1 Clock Dynamic mux that the switching happened
  [10] USART1_SCLK_SWITCHED — Indication from USART1 Clock Dynamic mux that the switching happened
  [9] QSPI_CLK_SWITCHED — Indication from QSPI Clock Dynamic mux that the switching happened
  [8] M4_SOC_CLK_SWITCHED — Indication from M4 SoC Clock Dynamic mux that the switching happened
  [7] PLL_LOCK_DATA_TRIG — This is set to 1'b1 when the PLL Locks are equal to pll_lock_int_data_reg
  [6] MODEMPLL_LOCK — Lock Signal from Modem PLL
  [5] SOCPLL_LOCK — Lock Signal from SoC PLL
  [4] I2SPLL_LOCK — Lock Signal from I2S PLL
  [3] INTFPLL_LOCK — Lock Signal from INTF PLL
  [2] APPLL_LOCK — Lock Signal from AP PLL
  [1] DDRPLL_LOCK — Lock Signal from DDR PLL
  [0] LCDPLL_LOCK — Lock Signal from LCD PLL
0x5C PLL_LOCK_INT_MASK_REG reset 0xFFFF — PLL Lock Interrupt Mask Register
  [31:16] Reserved1 — It is recommended to write these bits to 0.
  [15] PLL_LOCK_DATA_TRIGGER_MASK_BIT_OF_FALLING_EDGE — 1'b1 => Masked;1'b0 => Not Masked
  [14] MODEM_PLL_LOCK_MASK_BIT_OF_FALLING_EDGE — 1'b1 => Masked;1'b0 => Not Masked
  [13] SOC_PLL_LOCK_MASK_BIT_OF_FALLING_EDGE — 1'b1 => Masked;1'b0 => Not Masked
  [12] I2S_PLL_LOCK_MASK_BIT_OF_FALLING_EDGE — 1'b1 => Masked;1'b0 => Not Masked
  [11] INTF_PLL_LOCK_MASK_BIT_OF_FALLING_EDGE — 1'b1 => Masked;1'b0 => Not Masked
  [10] AP_PLL_LOCK_MASK_BIT_OF_FALLING_EDGE — 1'b1 => Masked;1'b0 => Not Masked
  [9] DDR_PLL_LOCK_MASK_BIT_OF_FALLING_EDGE — 1'b1 => Masked;1'b0 => Not Masked
  [8] LCD_PLL_LOCK_MASK_BIT_OF_FALLING_EDGE — 1'b1 => Masked;1'b0 => Not Masked
  [7] PLL_LOCK_DATA_TRIGGER_MASK_BIT_OF_RISING_EDGE — 1'b1 => Masked;1'b0 => Not Masked
  [6] MODEM_PLL_LOCK_MASK_BIT_OF_RISING_EDGE — 1'b1 => Masked;1'b0 => Not Masked
  [5] SOC_PLL_LOCK_MASK_BIT_OF_RISING_EDGE — 1'b1 => Masked;1'b0 => Not Masked
  [4] I2S_PLL_LOCK_MASK_BIT_OF_RISING_EDGE — 1'b1 => Masked;1'b0 => Not Masked
  [3] INTF_PLL_LOCK_MASK_BIT_OF_RISING_EDGE — 1'b1 => Masked;1'b0 => Not Masked
  [2] AP_PLL_LOCK_MASK_BIT_OF_RISING_EDGE — 1'b1 => Masked;1'b0 => Not Masked
  [1] DDR_PLL_LOCK_MASK_BIT_OF_RISING_EDGE — 1'b1 => Masked;1'b0 => Not Masked
  [0] LCD_PLL_LOCK_MASK_BIT_OF_RISING_EDGE — 1'b1 => Masked;1'b0 => Not Masked
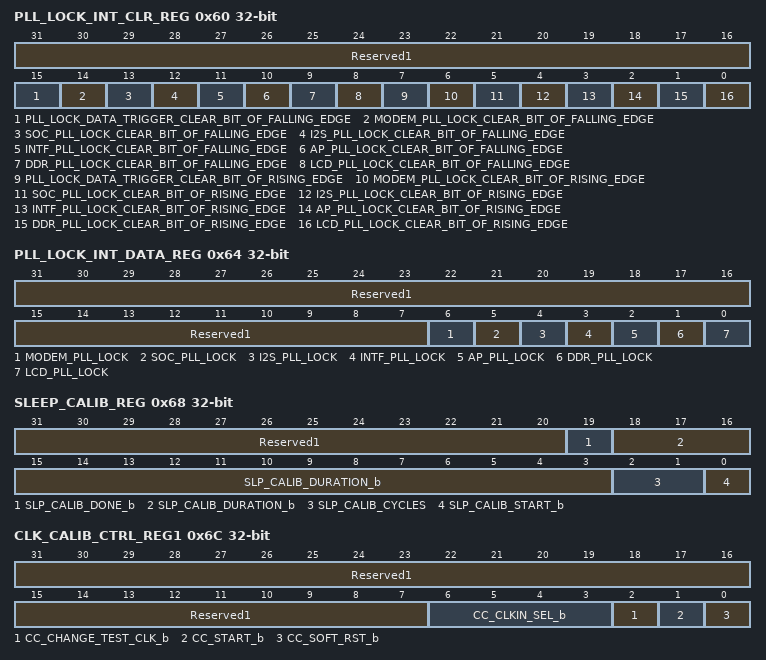
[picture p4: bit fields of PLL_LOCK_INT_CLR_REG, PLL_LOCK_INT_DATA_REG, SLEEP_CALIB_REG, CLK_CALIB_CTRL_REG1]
0x60 PLL_LOCK_INT_CLR_REG — PLL Lock Interrupt Clear Register
  [31:16] Reserved1 — It is recommended to write these bits to 0.
  [15] PLL_LOCK_DATA_TRIGGER_CLEAR_BIT_OF_FALLING_EDGE — 1'b0 => Not Cleared 1'b1 => Cleared
  [14] MODEM_PLL_LOCK_CLEAR_BIT_OF_FALLING_EDGE — 1'b0 => Not Cleared 1'b1 => Cleared
  [13] SOC_PLL_LOCK_CLEAR_BIT_OF_FALLING_EDGE — 1'b0 => Not Cleared 1'b1 => Cleared
  [12] I2S_PLL_LOCK_CLEAR_BIT_OF_FALLING_EDGE — 1'b0 => Not Cleared 1'b1 => Cleared
  [11] INTF_PLL_LOCK_CLEAR_BIT_OF_FALLING_EDGE — 1'b0 => Not Cleared 1'b1 => Cleared
  [10] AP_PLL_LOCK_CLEAR_BIT_OF_FALLING_EDGE — 1'b0 => Not Cleared 1'b1 => Cleared
  [9] DDR_PLL_LOCK_CLEAR_BIT_OF_FALLING_EDGE — 1'b0 => Not Cleared 1'b1 => Cleared
  [8] LCD_PLL_LOCK_CLEAR_BIT_OF_FALLING_EDGE — 1'b0 => Not Cleared 1'b1 => Cleared
  [7] PLL_LOCK_DATA_TRIGGER_CLEAR_BIT_OF_RISING_EDGE — 1'b0 => Not Cleared 1'b1 => Cleared
  [6] MODEM_PLL_LOCK_CLEAR_BIT_OF_RISING_EDGE — 1'b0 => Not Cleared 1'b1 => Cleared
  [5] SOC_PLL_LOCK_CLEAR_BIT_OF_RISING_EDGE — 1'b0 => Not Cleared 1'b1 => Cleared
  [4] I2S_PLL_LOCK_CLEAR_BIT_OF_RISING_EDGE — 1'b0 => Not Cleared 1'b1 => Cleared
  [3] INTF_PLL_LOCK_CLEAR_BIT_OF_RISING_EDGE — 1'b0 => Not Cleared 1'b1 => Cleared
  [2] AP_PLL_LOCK_CLEAR_BIT_OF_RISING_EDGE — 1'b0 => Not Cleared 1'b1 => Cleared
  [1] DDR_PLL_LOCK_CLEAR_BIT_OF_RISING_EDGE — 1'b0 => Not Cleared 1'b1 => Cleared
  [0] LCD_PLL_LOCK_CLEAR_BIT_OF_RISING_EDGE — 1'b0 => Not Cleared 1'b1 => Cleared
0x64 PLL_LOCK_INT_DATA_REG — PLL Lock Interrupt DATA Register
  [31:7] Reserved1 — It is recommended to write these bits to 0.
  [6] MODEM_PLL_LOCK — 1'b1 => Modem PLL Lock has to be used as trigger1'b0 => Modem PLL Lock not to be used as trigger
  [5] SOC_PLL_LOCK — 1'b1 => SoC PLL Lock has to be used as trigger1'b0 => SoC PLL Lock not to be used as trigger
  [4] I2S_PLL_LOCK — 1'b1 => I2S PLL Lock has to be used as trigger1'b0 => I2S PLL Lock not to be used as trigger
  [3] INTF_PLL_LOCK — 1'b1 => INTF PLL Lock has to be used as trigger1'b0 => INTF PLL Lock not to be used as trigger
  [2] AP_PLL_LOCK — 1'b1 => AP PLL Lock has to be used as trigger1'b0 => Ap PLL Lock not to be used as trigger
  [1] DDR_PLL_LOCK — 1'b1 => DDR PLL Lock has to be used as trigger1'b0 => DDR PLL Lock not to be used as trigger
  [0] LCD_PLL_LOCK — 1'b1 => LCD PLL Lock has to be used as trigger1'b0 => LCD PLL Lock not to be used as trigger
0x68 SLEEP_CALIB_REG — Sleep Calib Register
  [31:20] Reserved1 — It is recommended to write these bits to 0.
  [19] SLP_CALIB_DONE_b — Indicates the end of calibration
  [18:3] SLP_CALIB_DURATION_b — Duration of the sleep clock in terms of processor clocks. This has to be divided with number of calibration cycles to get number of clock cycles(reference clock) in single clock period). 1b1 - AP PLL Lock has to be used as trigger1b0 - Ap PLL Lock not to be used as trigger
  [2:1] SLP_CALIB_CYCLES — These bits are used to program the number of clock cycles over which clock calibration is to be done.
  [0] SLP_CALIB_START_b — This bit is used to start the calibration. 1b1 - Start calibration. slp_calib_duration should be loaded before this bit is set. This bit is self-clearing. When read, if high indicates the completion of calibration process.
0x6C CLK_CALIB_CTRL_REG1 — Clock Calib Control Register1
  [31:7] Reserved1 — It is recommended to write these bits to 0.
  [6:3] CC_CLKIN_SEL_b — select the clock to be calibrated 4d0 - ulp_ref_clk 4d1 - mems_ref_clk 4d2 - ulp_20mhz_ringosc_clk 4d3 - modem_pll_clk1 4d4 - modem_pll_clk2 4d5 - intf_pll_clk 4d6 - soc_pll_clk 4d7 - i2s_pll_clk 4d8 - sleep_clk 4d9 - bus_clkby2_apss2m4ss_sram 4d10, 4d14 - Invalid 4d15 - Gated
  [2] CC_CHANGE_TEST_CLK_b — change test clk. Set this bit to 1'b1 only when test_clk is being changed, else this should be 1'b0.
  [1] CC_START_b — start clk calibration 1b1 - start
  [0] CC_SOFT_RST_b — Soft Reset for clock calibrator 1b1 - reset enabled 1b0 - reset disabled.
0x70 CLK_CALIB_CTRL_REG2 — Clock Calib Control Register2
  [31:0] CC_NUM_REF_CLKS — number of ref_clk cycles to be considered for calibrating.
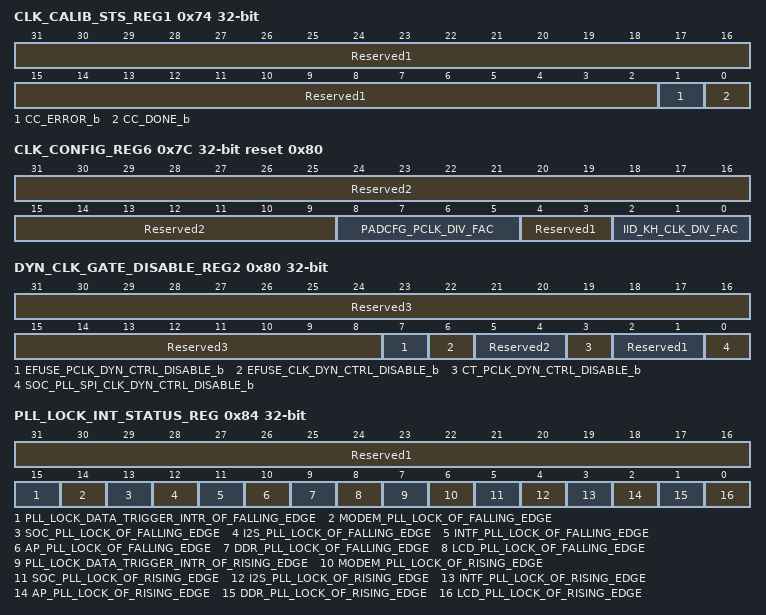
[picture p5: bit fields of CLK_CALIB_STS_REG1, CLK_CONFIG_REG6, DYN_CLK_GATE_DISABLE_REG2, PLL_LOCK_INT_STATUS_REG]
0x74 CLK_CALIB_STS_REG1 — Clock Calib Status Register1
  [31:2] Reserved1 — It is recommended to write these bits to 0.
  [1] CC_ERROR_b — indicates clock calibration error1'b1 => error1'b0 => none
  [0] CC_DONE_b — indicates clock calibratioon done1'b1 => done1'b0 => none
0x78 CLK_CALIB_STS_REG2 — Clock Calib Status Register2
  [31:0] CC_NUM_TEST_CLKS — number of test clk cycles occurred for the specified number of ref_clk cycles
0x7C CLK_CONFIG_REG6 reset 0x80 — Clock Config Register6
  [31:9] Reserved2 — It is recommended to write these bits to 0.
  [8:5] PADCFG_PCLK_DIV_FAC — Clock division factor for pclk_pad_config_m4ss
  [4:3] Reserved1 — It is recommended to write these bits to 0.
  [2:0] IID_KH_CLK_DIV_FAC — Clock division factor for iid_clk.
0x80 DYN_CLK_GATE_DISABLE_REG2 — Dynamic Clock Gate Disable Register2
  [31:8] Reserved3 — It is recommended to write these bits to 0.
  [7] EFUSE_PCLK_DYN_CTRL_DISABLE_b — Dynamic clock gate disable control efuse pclk 1b1 - Dynamic control of the clock is disbaled 1b0 - Dynamic control of the clock is enabled
  [6] EFUSE_CLK_DYN_CTRL_DISABLE_b — Dynamic clock gate disable control efuse clk 1b1 - Dynamic control of the clock is disbaled 1b0 - Dynamic control of the clock is enabled
  [5:4] Reserved2 — It is recommended to write these bits to 0.
  [3] CT_PCLK_DYN_CTRL_DISABLE_b — Dynamic clock gate disable control SCT pclk 1b1 - Dynamic control of the clock is disbaled 1b0 - Dynamic control of the clock is enabled
  [2:1] Reserved1 — It is recommended to write these bits to 0.
  [0] SOC_PLL_SPI_CLK_DYN_CTRL_DISABLE_b — Dynamic clock gate disable control soc pll spi clk 1b1 - Dynamic control of the clock is disbaled 1b0 - Dynamic control of the clock is enabled
0x84 PLL_LOCK_INT_STATUS_REG — PLL Lock Interrupt Status Register
  [31:16] Reserved1 — It is recommended to write these bits to 0.
  [15] PLL_LOCK_DATA_TRIGGER_INTR_OF_FALLING_EDGE — 1'b0 => No Interrupt;1'b1 => Interrupt encountered.
  [14] MODEM_PLL_LOCK_OF_FALLING_EDGE — 1'b0 => No Interrupt;1'b1 => Interrupt encountered.
  [13] SOC_PLL_LOCK_OF_FALLING_EDGE — 1'b0 => No Interrupt;1'b1 => Interrupt encountered.
  [12] I2S_PLL_LOCK_OF_FALLING_EDGE — 1'b0 => No Interrupt;1'b1 => Interrupt encountered.
  [11] INTF_PLL_LOCK_OF_FALLING_EDGE — 1'b0 => No Interrupt;1'b1 => Interrupt encountered.
  [10] AP_PLL_LOCK_OF_FALLING_EDGE — 1'b0 => No Interrupt;1'b1 => Interrupt encountered.
  [9] DDR_PLL_LOCK_OF_FALLING_EDGE — 1'b0 => No Interrupt;1'b1 => Interrupt encountered.
  [8] LCD_PLL_LOCK_OF_FALLING_EDGE — 1'b0 => No Interrupt;1'b1 => Interrupt encountered.
  [7] PLL_LOCK_DATA_TRIGGER_INTR_OF_RISING_EDGE — 1'b0 => No Interrupt;1'b1 => Interrupt encountered.
  [6] MODEM_PLL_LOCK_OF_RISING_EDGE — 1'b0 => No Interrupt;1'b1 => Interrupt encountered.
  [5] SOC_PLL_LOCK_OF_RISING_EDGE — 1'b0 => No Interrupt;1'b1 => Interrupt encountered.
  [4] I2S_PLL_LOCK_OF_RISING_EDGE — 1'b0 => No Interrupt;1'b1 => Interrupt encountered.
  [3] INTF_PLL_LOCK_OF_RISING_EDGE — 1'b0 => No Interrupt;1'b1 => Interrupt encountered.
  [2] AP_PLL_LOCK_OF_RISING_EDGE — 1'b0 => No Interrupt;1'b1 => Interrupt encountered.
  [1] DDR_PLL_LOCK_OF_RISING_EDGE — 1'b0 => No Interrupt;1'b1 => Interrupt encountered.
  [0] LCD_PLL_LOCK_OF_RISING_EDGE — 1b0 - No Interrupt; 1b1 - Interrupt encountered.
